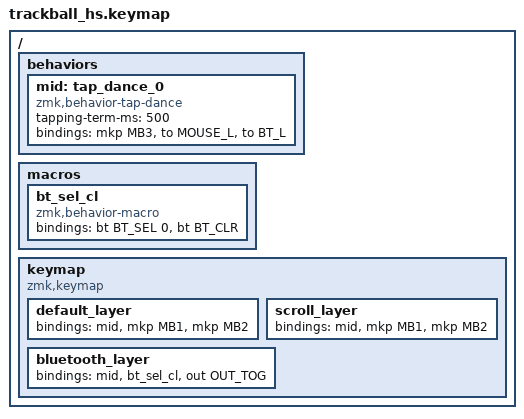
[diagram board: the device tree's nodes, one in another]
/*
 * Copyright (c) 2021-2022 The ZMK Contributors
 *
 * SPDX-License-Identifier: MIT
 */

#include <behaviors.dtsi>
#include <dt-bindings/zmk/bt.h>
#include <dt-bindings/zmk/keys.h>
#include <dt-bindings/zmk/outputs.h>
#include <dt-bindings/zmk/pointing.h>

#define MOUSE_L		0
#define SCROLL_L 	1
#define BT_L 		2


/ {
    behaviors {
        mid: tap_dance_0 {
            compatible = "zmk,behavior-tap-dance";
            #binding-cells = <0>;
            tapping-term-ms = <500>;
            bindings = <&mkp MB3>, <&to MOUSE_L>, <&to BT_L>;
        };
    };
    macros {
        bt_sel_cl: bt_sel_cl {
            compatible = "zmk,behavior-macro";
            #binding-cells = <0>;
            bindings
                = <&bt BT_SEL 0>
                , <&bt BT_CLR>
		;
        };
    };
        keymap {
                compatible = "zmk,keymap";

                default_layer {
/* MOUSE
 * -----------------
 * |       |   MMB   | 
 * | LMB   |   RMB   |
 */
                        bindings = <
						&mid
				&mkp MB1        &mkp MB2
                        >;
                };
	
                scroll_layer {
/* SCROLL
 * -----------------
 * |       |   MMB   | 
 * | LMB   |   RMB   |
 */
                        bindings = <
						&mid
				&mkp MB1        &mkp MB2
                        >;
                };
                bluetooth_layer {
/* BlueTooth setup layer
 * -----------------
 * |       |   MMB   | 
 * | LMB   |   RMB   |
 */
                        bindings = <
						&mid
				&bt_sel_cl      &out  OUT_TOG
                        >;
                };
        };
};
